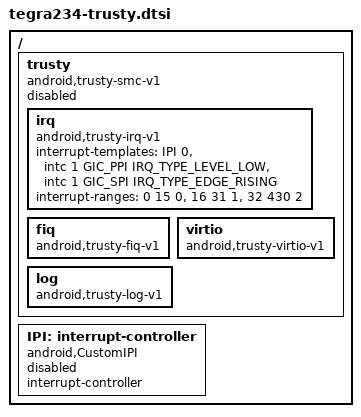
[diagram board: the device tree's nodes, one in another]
/*
 * Copyright (c) 2016-2020, NVIDIA CORPORATION.  All rights reserved.
 *
 * This program is free software; you can redistribute it and/or modify it
 * under the terms and conditions of the GNU General Public License,
 * version 2, as published by the Free Software Foundation.
 *
 * This program is distributed in the hope it will be useful, but WITHOUT
 * ANY WARRANTY; without even the implied warranty of MERCHANTABILITY or
 * FITNESS FOR A PARTICULAR PURPOSE.  See the GNU General Public License for
 * more details.
 *
 * You should have received a copy of the GNU General Public License
 * along with this program.  If not, see <http://www.gnu.org/licenses/>.
 */

/ {
	trusty {
		compatible = "android,trusty-smc-v1";
		ranges;
		#address-cells = <2>;
		#size-cells = <2>;
		status = "disabled";

		irq {
			compatible = "android,trusty-irq-v1";
			interrupt-templates = <&IPI 0>,
					      <&intc 1 GIC_PPI IRQ_TYPE_LEVEL_LOW>,
					      <&intc 1 GIC_SPI IRQ_TYPE_EDGE_RISING>;
			interrupt-ranges = < 0  15 0>,
					   <16  31 1>,
					   <32 430 2>;
		};

		fiq {
			compatible = "android,trusty-fiq-v1";
		};

		virtio {
			compatible = "android,trusty-virtio-v1";
		};

		log {
			compatible = "android,trusty-log-v1";
		};
	};

	IPI: interrupt-controller {
		compatible = "android,CustomIPI";
		#interrupt-cells = <1>;
		interrupt-controller;
		status = "disabled";
	};
};
